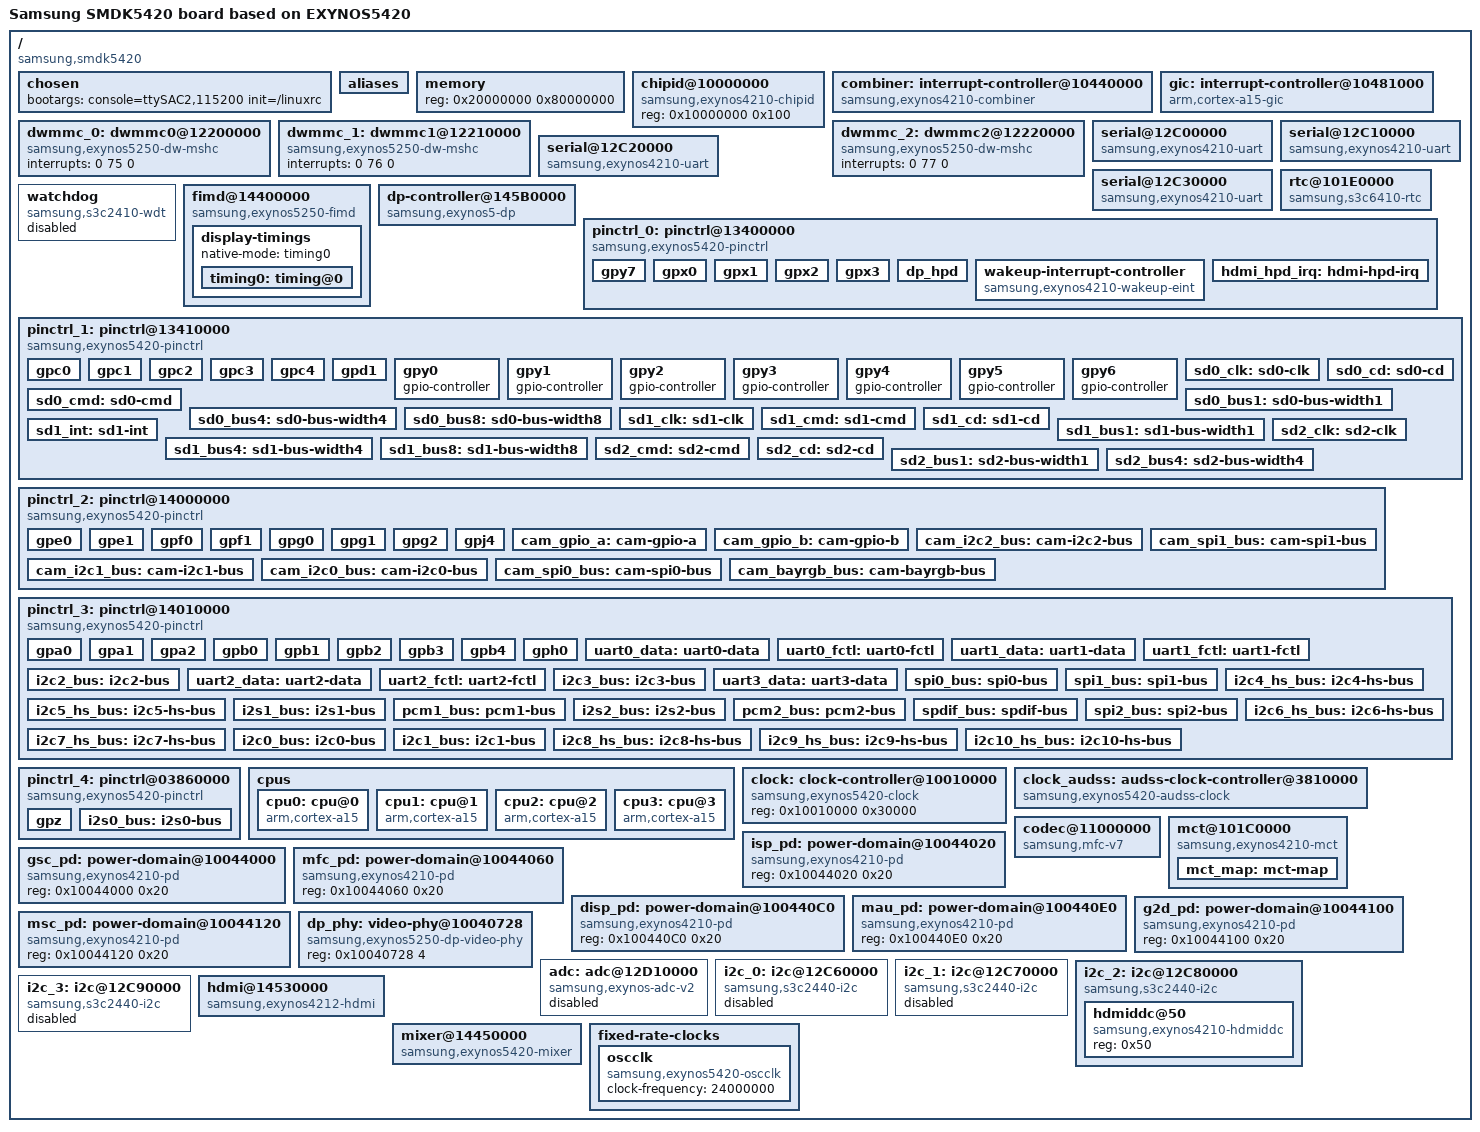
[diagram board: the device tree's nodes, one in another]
/*
 * SAMSUNG SMDK5420 board device tree source
 *
 * Copyright (c) 2013 Samsung Electronics Co., Ltd.
 *		http://www.samsung.com
 *
 * This program is free software; you can redistribute it and/or modify
 * it under the terms of the GNU General Public License version 2 as
 * published by the Free Software Foundation.
*/



/* #include "skeleton.dtsi" */

/ {
	/* ARM10C 20131012 */
	#address-cells = <1>;
	#size-cells = <1>;
	chosen { };
	aliases { };
	memory { device_type = "memory"; reg = <0 0>; };
};

/* #include "exynos5.dtsi" */

/ {
	interrupt-parent = <&gic>;

	chipid@10000000 {
		compatible = "samsung,exynos4210-chipid";
		reg = <0x10000000 0x100>;
	};

	combiner:interrupt-controller@10440000 {
		compatible = "samsung,exynos4210-combiner";
		#interrupt-cells = <2>;
		interrupt-controller;
		samsung,combiner-nr = <32>;
		reg = <0x10440000 0x1000>;
		interrupts =	<0 0 0>, <0 1 0>, <0 2 0>, <0 3 0>,
				<0 4 0>, <0 5 0>, <0 6 0>, <0 7 0>,
				<0 8 0>, <0 9 0>, <0 10 0>, <0 11 0>,
				<0 12 0>, <0 13 0>, <0 14 0>, <0 15 0>,
				<0 16 0>, <0 17 0>, <0 18 0>, <0 19 0>,
				<0 20 0>, <0 21 0>, <0 22 0>, <0 23 0>,
				<0 24 0>, <0 25 0>, <0 26 0>, <0 27 0>,
				<0 28 0>, <0 29 0>, <0 30 0>, <0 31 0>;
	};

	gic:interrupt-controller@10481000 {
		compatible = "arm,cortex-a15-gic", "arm,cortex-a9-gic";
		#interrupt-cells = <3>;
		interrupt-controller;
		reg =	<0x10481000 0x1000>,
			<0x10482000 0x1000>,
			<0x10484000 0x2000>,
			<0x10486000 0x2000>;
		interrupts = <1 9 0xf04>;
	};

	dwmmc_0: dwmmc0@12200000 {
		compatible = "samsung,exynos5250-dw-mshc";
		interrupts = <0 75 0>;
		#address-cells = <1>;
		#size-cells = <0>;
	};

	dwmmc_1: dwmmc1@12210000 {
		compatible = "samsung,exynos5250-dw-mshc";
		interrupts = <0 76 0>;
		#address-cells = <1>;
		#size-cells = <0>;
	};

	dwmmc_2: dwmmc2@12220000 {
		compatible = "samsung,exynos5250-dw-mshc";
		interrupts = <0 77 0>;
		#address-cells = <1>;
		#size-cells = <0>;
	};

	serial@12C00000 {
		compatible = "samsung,exynos4210-uart";
		reg = <0x12C00000 0x100>;
		interrupts = <0 51 0>;
	};

	serial@12C10000 {
		compatible = "samsung,exynos4210-uart";
		reg = <0x12C10000 0x100>;
		interrupts = <0 52 0>;
	};

	serial@12C20000 {
		compatible = "samsung,exynos4210-uart";
		reg = <0x12C20000 0x100>;
		interrupts = <0 53 0>;
	};

	serial@12C30000 {
		compatible = "samsung,exynos4210-uart";
		reg = <0x12C30000 0x100>;
		interrupts = <0 54 0>;
	};

	rtc@101E0000 {
		compatible = "samsung,s3c6410-rtc";
		reg = <0x101E0000 0x100>;
		interrupts = <0 43 0>, <0 44 0>;
		status = "disabled";
	};

	watchdog {
		compatible = "samsung,s3c2410-wdt";
		reg = <0x101D0000 0x100>;
		interrupts = <0 42 0>;
		status = "disabled";
	};

	fimd@14400000 {
		compatible = "samsung,exynos5250-fimd";
		interrupt-parent = <&combiner>;
		reg = <0x14400000 0x40000>;
		interrupt-names = "fifo", "vsync", "lcd_sys";
		interrupts = <18 4>, <18 5>, <18 6>;
		status = "disabled";
	};

	dp-controller@145B0000 {
		compatible = "samsung,exynos5-dp";
		reg = <0x145B0000 0x1000>;
		interrupts = <10 3>;
		interrupt-parent = <&combiner>;
		#address-cells = <1>;
		#size-cells = <0>;
		status = "disabled";
	};
};

/* #include "exynos5420-pinctrl.dtsi" */
/ {
	pinctrl@13400000 {
		gpy7: gpy7 {
			gpio-controller;
			#gpio-cells = <2>;

			interrupt-controller;
			#interrupt-cells = <2>;
		};

		gpx0: gpx0 {
			gpio-controller;
			#gpio-cells = <2>;

			interrupt-controller;
			interrupt-parent = <&combiner>;
			#interrupt-cells = <2>;
			interrupts = <23 0>, <24 0>, <25 0>, <25 1>,
				     <26 0>, <26 1>, <27 0>, <27 1>;
		};

		gpx1: gpx1 {
			gpio-controller;
			#gpio-cells = <2>;

			interrupt-controller;
			interrupt-parent = <&combiner>;
			#interrupt-cells = <2>;
			interrupts = <28 0>, <28 1>, <29 0>, <29 1>,
				     <30 0>, <30 1>, <31 0>, <31 1>;
		};

		gpx2: gpx2 {
			gpio-controller;
			#gpio-cells = <2>;

			interrupt-controller;
			#interrupt-cells = <2>;
		};

		gpx3: gpx3 {
			gpio-controller;
			#gpio-cells = <2>;

			interrupt-controller;
			#interrupt-cells = <2>;
		};

		dp_hpd: dp_hpd {
			samsung,pins = "gpx0-7";
			samsung,pin-function = <3>;
			samsung,pin-pud = <0>;
			samaung,pin-drv = <0>;
		};
	};

	pinctrl@13410000 {
		gpc0: gpc0 {
			gpio-controller;
			#gpio-cells = <2>;

			interrupt-controller;
			#interrupt-cells = <2>;
		};

		gpc1: gpc1 {
			gpio-controller;
			#gpio-cells = <2>;

			interrupt-controller;
			#interrupt-cells = <2>;
		};

		gpc2: gpc2 {
			gpio-controller;
			#gpio-cells = <2>;

			interrupt-controller;
			#interrupt-cells = <2>;
		};

		gpc3: gpc3 {
			gpio-controller;
			#gpio-cells = <2>;

			interrupt-controller;
			#interrupt-cells = <2>;
		};

		gpc4: gpc4 {
			gpio-controller;
			#gpio-cells = <2>;

			interrupt-controller;
			#interrupt-cells = <2>;
		};

		gpd1: gpd1 {
			gpio-controller;
			#gpio-cells = <2>;

			interrupt-controller;
			#interrupt-cells = <2>;
		};

		gpy0: gpy0 {
			gpio-controller;
			#gpio-cells = <2>;
		};

		gpy1: gpy1 {
			gpio-controller;
			#gpio-cells = <2>;
		};

		gpy2: gpy2 {
			gpio-controller;
			#gpio-cells = <2>;
		};

		gpy3: gpy3 {
			gpio-controller;
			#gpio-cells = <2>;
		};

		gpy4: gpy4 {
			gpio-controller;
			#gpio-cells = <2>;
		};

		gpy5: gpy5 {
			gpio-controller;
			#gpio-cells = <2>;
		};

		gpy6: gpy6 {
			gpio-controller;
			#gpio-cells = <2>;
		};

		sd0_clk: sd0-clk {
			samsung,pins = "gpc0-0";
			samsung,pin-function = <2>;
			samsung,pin-pud = <0>;
			samsung,pin-drv = <3>;
		};

		sd0_cmd: sd0-cmd {
			samsung,pins = "gpc0-1";
			samsung,pin-function = <2>;
			samsung,pin-pud = <0>;
			samsung,pin-drv = <3>;
		};

		sd0_cd: sd0-cd {
			samsung,pins = "gpc0-2";
			samsung,pin-function = <2>;
			samsung,pin-pud = <3>;
			samsung,pin-drv = <3>;
		};

		sd0_bus1: sd0-bus-width1 {
			samsung,pins = "gpc0-3";
			samsung,pin-function = <2>;
			samsung,pin-pud = <3>;
			samsung,pin-drv = <3>;
		};

		sd0_bus4: sd0-bus-width4 {
			samsung,pins = "gpc0-4", "gpc0-5", "gpc0-6";
			samsung,pin-function = <2>;
			samsung,pin-pud = <3>;
			samsung,pin-drv = <3>;
		};

		sd0_bus8: sd0-bus-width8 {
			samsung,pins = "gpc3-0", "gpc3-1", "gpc3-2", "gpc3-3";
			samsung,pin-function = <2>;
			samsung,pin-pud = <3>;
			samsung,pin-drv = <3>;
		};

		sd1_clk: sd1-clk {
			samsung,pins = "gpc1-0";
			samsung,pin-function = <2>;
			samsung,pin-pud = <0>;
			samsung,pin-drv = <3>;
		};

		sd1_cmd: sd1-cmd {
			samsung,pins = "gpc1-1";
			samsung,pin-function = <2>;
			samsung,pin-pud = <0>;
			samsung,pin-drv = <3>;
		};

		sd1_cd: sd1-cd {
			samsung,pins = "gpc1-2";
			samsung,pin-function = <2>;
			samsung,pin-pud = <3>;
			samsung,pin-drv = <3>;
		};

		sd1_int: sd1-int {
			samsung,pins = "gpd1-1";
			samsung,pin-function = <2>;
			samsung,pin-pud = <3>;
			samsung,pin-drv = <0>;
		};

		sd1_bus1: sd1-bus-width1 {
			samsung,pins = "gpc1-3";
			samsung,pin-function = <2>;
			samsung,pin-pud = <3>;
			samsung,pin-drv = <3>;
		};

		sd1_bus4: sd1-bus-width4 {
			samsung,pins = "gpc1-4", "gpc1-5", "gpc1-6";
			samsung,pin-function = <2>;
			samsung,pin-pud = <3>;
			samsung,pin-drv = <3>;
		};

		sd1_bus8: sd1-bus-width8 {
			samsung,pins = "gpd1-4", "gpd1-5", "gpd1-6", "gpd1-7";
			samsung,pin-function = <2>;
			samsung,pin-pud = <3>;
			samsung,pin-drv = <3>;
		};

		sd2_clk: sd2-clk {
			samsung,pins = "gpc2-0";
			samsung,pin-function = <2>;
			samsung,pin-pud = <0>;
			samsung,pin-drv = <3>;
		};

		sd2_cmd: sd2-cmd {
			samsung,pins = "gpc2-1";
			samsung,pin-function = <2>;
			samsung,pin-pud = <0>;
			samsung,pin-drv = <3>;
		};

		sd2_cd: sd2-cd {
			samsung,pins = "gpc2-2";
			samsung,pin-function = <2>;
			samsung,pin-pud = <3>;
			samsung,pin-drv = <3>;
		};

		sd2_bus1: sd2-bus-width1 {
			samsung,pins = "gpc2-3";
			samsung,pin-function = <2>;
			samsung,pin-pud = <3>;
			samsung,pin-drv = <3>;
		};

		sd2_bus4: sd2-bus-width4 {
			samsung,pins = "gpc2-4", "gpc2-5", "gpc2-6";
			samsung,pin-function = <2>;
			samsung,pin-pud = <3>;
			samsung,pin-drv = <3>;
		};
	};

	pinctrl@14000000 {
		gpe0: gpe0 {
			gpio-controller;
			#gpio-cells = <2>;

			interrupt-controller;
			#interrupt-cells = <2>;
		};

		gpe1: gpe1 {
			gpio-controller;
			#gpio-cells = <2>;

			interrupt-controller;
			#interrupt-cells = <2>;
		};

		gpf0: gpf0 {
			gpio-controller;
			#gpio-cells = <2>;

			interrupt-controller;
			#interrupt-cells = <2>;
		};

		gpf1: gpf1 {
			gpio-controller;
			#gpio-cells = <2>;

			interrupt-controller;
			#interrupt-cells = <2>;
		};

		gpg0: gpg0 {
			gpio-controller;
			#gpio-cells = <2>;

			interrupt-controller;
			#interrupt-cells = <2>;
		};

		gpg1: gpg1 {
			gpio-controller;
			#gpio-cells = <2>;

			interrupt-controller;
			#interrupt-cells = <2>;
		};

		gpg2: gpg2 {
			gpio-controller;
			#gpio-cells = <2>;

			interrupt-controller;
			#interrupt-cells = <2>;
		};

		gpj4: gpj4 {
			gpio-controller;
			#gpio-cells = <2>;

			interrupt-controller;
			#interrupt-cells = <2>;
		};

		cam_gpio_a: cam-gpio-a {
			samsung,pins = "gpe0-0", "gpe0-1", "gpe0-2", "gpe0-3",
				       "gpe0-4", "gpe0-5", "gpe0-6", "gpe0-7",
				       "gpe1-0", "gpe1-1";
			samsung,pin-function = <2>;
			samsung,pin-pud = <0>;
			samsung,pin-drv = <0>;
		};

		cam_gpio_b: cam-gpio-b {
			samsung,pins = "gpf0-0", "gpf0-1", "gpf0-2", "gpf0-3",
				       "gpf1-0", "gpf1-1", "gpf1-2", "gpf1-3";
			samsung,pin-function = <3>;
			samsung,pin-pud = <0>;
			samsung,pin-drv = <0>;
		};

		cam_i2c2_bus: cam-i2c2-bus {
			samsung,pins = "gpf0-4", "gpf0-5";
			samsung,pin-function = <2>;
			samsung,pin-pud = <3>;
			samsung,pin-drv = <0>;
		};
		cam_spi1_bus: cam-spi1-bus {
			samsung,pins = "gpe0-4", "gpe0-5", "gpf0-2", "gpf0-3";
			samsung,pin-function = <4>;
			samsung,pin-pud = <0>;
			samsung,pin-drv = <0>;
		};

		cam_i2c1_bus: cam-i2c1-bus {
			samsung,pins = "gpf0-2", "gpf0-3";
			samsung,pin-function = <2>;
			samsung,pin-pud = <3>;
			samsung,pin-drv = <0>;
		};

		cam_i2c0_bus: cam-i2c0-bus {
			samsung,pins = "gpf0-0", "gpf0-1";
			samsung,pin-function = <2>;
			samsung,pin-pud = <3>;
			samsung,pin-drv = <0>;
		};

		cam_spi0_bus: cam-spi0-bus {
			samsung,pins = "gpf1-0", "gpf1-1", "gpf1-2", "gpf1-3";
			samsung,pin-function = <2>;
			samsung,pin-pud = <0>;
			samsung,pin-drv = <0>;
		};

		cam_bayrgb_bus: cam-bayrgb-bus {
			samsung,pins = "gpg0-0", "gpg0-1", "gpg0-2", "gpg0-3",
				       "gpg0-4", "gpg0-5", "gpg0-6", "gpg0-7",
				       "gpg1-0", "gpg1-1", "gpg1-2", "gpg1-3",
				       "gpg1-4", "gpg1-5", "gpg1-6", "gpg1-7",
				       "gpg2-0";
			samsung,pin-function = <2>;
			samsung,pin-pud = <0>;
			samsung,pin-drv = <0>;
		};
	};

	pinctrl@14010000 {
		gpa0: gpa0 {
			gpio-controller;
			#gpio-cells = <2>;

			interrupt-controller;
			#interrupt-cells = <2>;
		};

		gpa1: gpa1 {
			gpio-controller;
			#gpio-cells = <2>;

			interrupt-controller;
			#interrupt-cells = <2>;
		};

		gpa2: gpa2 {
			gpio-controller;
			#gpio-cells = <2>;

			interrupt-controller;
			#interrupt-cells = <2>;
		};

		gpb0: gpb0 {
			gpio-controller;
			#gpio-cells = <2>;

			interrupt-controller;
			#interrupt-cells = <2>;
		};

		gpb1: gpb1 {
			gpio-controller;
			#gpio-cells = <2>;

			interrupt-controller;
			#interrupt-cells = <2>;
		};

		gpb2: gpb2 {
			gpio-controller;
			#gpio-cells = <2>;

			interrupt-controller;
			#interrupt-cells = <2>;
		};

		gpb3: gpb3 {
			gpio-controller;
			#gpio-cells = <2>;

			interrupt-controller;
			#interrupt-cells = <2>;
		};

		gpb4: gpb4 {
			gpio-controller;
			#gpio-cells = <2>;

			interrupt-controller;
			#interrupt-cells = <2>;
		};

		gph0: gph0 {
			gpio-controller;
			#gpio-cells = <2>;

			interrupt-controller;
			#interrupt-cells = <2>;
		};

		uart0_data: uart0-data {
			samsung,pins = "gpa0-0", "gpa0-1";
			samsung,pin-function = <2>;
			samsung,pin-pud = <0>;
			samsung,pin-drv = <0>;
		};

		uart0_fctl: uart0-fctl {
			samsung,pins = "gpa0-2", "gpa0-3";
			samsung,pin-function = <2>;
			samsung,pin-pud = <0>;
			samsung,pin-drv = <0>;
		};

		uart1_data: uart1-data {
			samsung,pins = "gpa0-4", "gpa0-5";
			samsung,pin-function = <2>;
			samsung,pin-pud = <0>;
			samsung,pin-drv = <0>;
		};

		uart1_fctl: uart1-fctl {
			samsung,pins = "gpa0-6", "gpa0-7";
			samsung,pin-function = <2>;
			samsung,pin-pud = <0>;
			samsung,pin-drv = <0>;
		};

		i2c2_bus: i2c2-bus {
			samsung,pins = "gpa0-6", "gpa0-7";
			samsung,pin-function = <3>;
			samsung,pin-pud = <3>;
			samsung,pin-drv = <0>;
		};

		uart2_data: uart2-data {
			samsung,pins = "gpa1-0", "gpa1-1";
			samsung,pin-function = <2>;
			samsung,pin-pud = <0>;
			samsung,pin-drv = <0>;
		};

		uart2_fctl: uart2-fctl {
			samsung,pins = "gpa1-2", "gpa1-3";
			samsung,pin-function = <2>;
			samsung,pin-pud = <0>;
			samsung,pin-drv = <0>;
		};

		i2c3_bus: i2c3-bus {
			samsung,pins = "gpa1-2", "gpa1-3";
			samsung,pin-function = <3>;
			samsung,pin-pud = <3>;
			samsung,pin-drv = <0>;
		};

		uart3_data: uart3-data {
			samsung,pins = "gpa1-4", "gpa1-5";
			samsung,pin-function = <2>;
			samsung,pin-pud = <0>;
			samsung,pin-drv = <0>;
		};

		spi0_bus: spi0-bus {
			samsung,pins = "gpa2-0", "gpa2-1", "gpa2-2", "gpa2-3";
			samsung,pin-function = <2>;
			samsung,pin-pud = <3>;
			samsung,pin-drv = <0>;
		};

		spi1_bus: spi1-bus {
			samsung,pins = "gpa2-4", "gpa2-6", "gpa2-7";
			samsung,pin-function = <2>;
			samsung,pin-pud = <3>;
			samsung,pin-drv = <0>;
		};

		i2c4_hs_bus: i2c4-hs-bus {
			samsung,pins = "gpa2-0", "gpa2-1";
			samsung,pin-function = <3>;
			samsung,pin-pud = <3>;
			samsung,pin-drv = <0>;
		};

		i2c5_hs_bus: i2c5-hs-bus {
			samsung,pins = "gpa2-2", "gpa2-3";
			samsung,pin-function = <3>;
			samsung,pin-pud = <3>;
			samsung,pin-drv = <0>;
		};

		i2s1_bus: i2s1-bus {
			samsung,pins = "gpb0-0", "gpb0-1", "gpb0-2", "gpb0-3",
					"gpb0-4";
			samsung,pin-function = <2>;
			samsung,pin-pud = <0>;
			samsung,pin-drv = <0>;
		};

		pcm1_bus: pcm1-bus {
			samsung,pins = "gpb0-0", "gpb0-1", "gpb0-2", "gpb0-3",
					"gpb0-4";
			samsung,pin-function = <3>;
			samsung,pin-pud = <0>;
			samsung,pin-drv = <0>;
		};

		i2s2_bus: i2s2-bus {
			samsung,pins = "gpb1-0", "gpb1-1", "gpb1-2", "gpb1-3",
					"gpb1-4";
			samsung,pin-function = <2>;
			samsung,pin-pud = <0>;
			samsung,pin-drv = <0>;
		};

		pcm2_bus: pcm2-bus {
			samsung,pins = "gpb1-0", "gpb1-1", "gpb1-2", "gpb1-3",
					"gpb1-4";
			samsung,pin-function = <3>;
			samsung,pin-pud = <0>;
			samsung,pin-drv = <0>;
		};

		spdif_bus: spdif-bus {
			samsung,pins = "gpb1-0", "gpb1-1";
			samsung,pin-function = <4>;
			samsung,pin-pud = <0>;
			samsung,pin-drv = <0>;
		};

		spi2_bus: spi2-bus {
			samsung,pins = "gpb1-1", "gpb1-3", "gpb1-4";
			samsung,pin-function = <5>;
			samsung,pin-pud = <3>;
			samsung,pin-drv = <0>;
		};

		i2c6_hs_bus: i2c6-hs-bus {
			samsung,pins = "gpb1-3", "gpb1-4";
			samsung,pin-function = <4>;
			samsung,pin-pud = <3>;
			samsung,pin-drv = <0>;
		};

		i2c7_hs_bus: i2c7-hs-bus {
			samsung,pins = "gpb2-2", "gpb2-3";
			samsung,pin-function = <3>;
			samsung,pin-pud = <3>;
			samsung,pin-drv = <0>;
		};

		i2c0_bus: i2c0-bus {
			samsung,pins = "gpb3-0", "gpb3-1";
			samsung,pin-function = <2>;
			samsung,pin-pud = <3>;
			samsung,pin-drv = <0>;
		};

		i2c1_bus: i2c1-bus {
			samsung,pins = "gpb3-2", "gpb3-3";
			samsung,pin-function = <2>;
			samsung,pin-pud = <3>;
			samsung,pin-drv = <0>;
		};

		i2c8_hs_bus: i2c8-hs-bus {
			samsung,pins = "gpb3-4", "gpb3-5";
			samsung,pin-function = <2>;
			samsung,pin-pud = <3>;
			samsung,pin-drv = <0>;
		};

		i2c9_hs_bus: i2c9-hs-bus {
			samsung,pins = "gpb3-6", "gpb3-7";
			samsung,pin-function = <2>;
			samsung,pin-pud = <3>;
			samsung,pin-drv = <0>;
		};

		i2c10_hs_bus: i2c10-hs-bus {
			samsung,pins = "gpb4-0", "gpb4-1";
			samsung,pin-function = <2>;
			samsung,pin-pud = <3>;
			samsung,pin-drv = <0>;
		};
	};

	pinctrl@03860000 {
		gpz: gpz {
			gpio-controller;
			#gpio-cells = <2>;

			interrupt-controller;
			#interrupt-cells = <2>;
		};

		i2s0_bus: i2s0-bus {
			samsung,pins = "gpz-0", "gpz-1", "gpz-2", "gpz-3",
					"gpz-4", "gpz-5", "gpz-6";
			samsung,pin-function = <2>;
			samsung,pin-pud = <0>;
			samsung,pin-drv = <0>;
		};
	};
};

/* #include <dt-bindings/clk/exynos-audss-clk.h> */
#ifndef _DT_BINDINGS_CLK_EXYNOS_AUDSS_H
#define _DT_BINDINGS_CLK_EXYNOS_AUDSS_H

#define EXYNOS_MOUT_AUDSS	0
#define EXYNOS_MOUT_I2S	1
#define EXYNOS_DOUT_SRP	2
#define EXYNOS_DOUT_AUD_BUS	3
#define EXYNOS_DOUT_I2S	4
#define EXYNOS_SRP_CLK		5
#define EXYNOS_I2S_BUS		6
#define EXYNOS_SCLK_I2S	7
#define EXYNOS_PCM_BUS		8
#define EXYNOS_SCLK_PCM	9

#define EXYNOS_AUDSS_MAX_CLKS	10

#endif

/* #include "exynos5420.dtsi" */

/ {
	compatible = "samsung,exynos5420";

	aliases {
		pinctrl0 = &pinctrl_0;
		pinctrl1 = &pinctrl_1;
		pinctrl2 = &pinctrl_2;
		pinctrl3 = &pinctrl_3;
		pinctrl4 = &pinctrl_4;
		i2c0 = &i2c_0;
		i2c1 = &i2c_1;
		i2c2 = &i2c_2;
		i2c3 = &i2c_3;
	};

	cpus {
		#address-cells = <1>;
		#size-cells = <0>;

		cpu0: cpu@0 {
			device_type = "cpu";
			compatible = "arm,cortex-a15";
			reg = <0x0>;
			clock-frequency = <1800000000>;
		};

		cpu1: cpu@1 {
			device_type = "cpu";
			compatible = "arm,cortex-a15";
			reg = <0x1>;
			clock-frequency = <1800000000>;
		};

		cpu2: cpu@2 {
			device_type = "cpu";
			compatible = "arm,cortex-a15";
			reg = <0x2>;
			clock-frequency = <1800000000>;
		};

		cpu3: cpu@3 {
			device_type = "cpu";
			compatible = "arm,cortex-a15";
			reg = <0x3>;
			clock-frequency = <1800000000>;
		};
	};

	clock: clock-controller@10010000 {
		compatible = "samsung,exynos5420-clock";
		reg = <0x10010000 0x30000>;
		#clock-cells = <1>;
	};

	clock_audss: audss-clock-controller@3810000 {
		compatible = "samsung,exynos5420-audss-clock";
		reg = <0x03810000 0x0C>;
		#clock-cells = <1>;
		clocks = <&clock 148>;
		clock-names = "sclk_audio";
	};

	codec@11000000 {
		compatible = "samsung,mfc-v7";
		reg = <0x11000000 0x10000>;
		interrupts = <0 96 0>;
		clocks = <&clock 401>;
		clock-names = "mfc";
	};

	mct@101C0000 {
		compatible = "samsung,exynos4210-mct";
		reg = <0x101C0000 0x800>;
		interrupt-controller;
		#interrups-cells = <1>;
		interrupt-parent = <&mct_map>;
		interrupts = <0>, <1>, <2>, <3>, <4>, <5>, <6>, <7>;
		clocks = <&clock 1>, <&clock 315>;
		clock-names = "fin_pll", "mct";

		mct_map: mct-map {
			#interrupt-cells = <1>;
			#address-cells = <0>;
			#size-cells = <0>;
			interrupt-map = <0 &combiner 23 3>,
					<1 &combiner 23 4>,
					<2 &combiner 25 2>,
					<3 &combiner 25 3>,
					<4 &gic 0 120 0>,
					<5 &gic 0 121 0>,
					<6 &gic 0 122 0>,
					<7 &gic 0 123 0>;
		};
	};

	gsc_pd: power-domain@10044000 {
		compatible = "samsung,exynos4210-pd";
		reg = <0x10044000 0x20>;
	};

	isp_pd: power-domain@10044020 {
		compatible = "samsung,exynos4210-pd";
		reg = <0x10044020 0x20>;
	};

	mfc_pd: power-domain@10044060 {
		compatible = "samsung,exynos4210-pd";
		reg = <0x10044060 0x20>;
	};

	disp_pd: power-domain@100440C0 {
		compatible = "samsung,exynos4210-pd";
		reg = <0x100440C0 0x20>;
	};

	mau_pd: power-domain@100440E0 {
		compatible = "samsung,exynos4210-pd";
		reg = <0x100440E0 0x20>;
	};

	g2d_pd: power-domain@10044100 {
		compatible = "samsung,exynos4210-pd";
		reg = <0x10044100 0x20>;
	};

	msc_pd: power-domain@10044120 {
		compatible = "samsung,exynos4210-pd";
		reg = <0x10044120 0x20>;
	};

	pinctrl_0: pinctrl@13400000 {
		compatible = "samsung,exynos5420-pinctrl";
		reg = <0x13400000 0x1000>;
		interrupts = <0 45 0>;

		wakeup-interrupt-controller {
			compatible = "samsung,exynos4210-wakeup-eint";
			interrupt-parent = <&gic>;
			interrupts = <0 32 0>;
		};
	};

	pinctrl_1: pinctrl@13410000 {
		compatible = "samsung,exynos5420-pinctrl";
		reg = <0x13410000 0x1000>;
		interrupts = <0 78 0>;
	};

	pinctrl_2: pinctrl@14000000 {
		compatible = "samsung,exynos5420-pinctrl";
		reg = <0x14000000 0x1000>;
		interrupts = <0 46 0>;
	};

	pinctrl_3: pinctrl@14010000 {
		compatible = "samsung,exynos5420-pinctrl";
		reg = <0x14010000 0x1000>;
		interrupts = <0 50 0>;
	};

	pinctrl_4: pinctrl@03860000 {
		compatible = "samsung,exynos5420-pinctrl";
		reg = <0x03860000 0x1000>;
		interrupts = <0 47 0>;
	};

	rtc@101E0000 {
		clocks = <&clock 317>;
		clock-names = "rtc";
		status = "okay";
	};

	serial@12C00000 {
		clocks = <&clock 257>, <&clock 128>;
		clock-names = "uart", "clk_uart_baud0";
	};

	serial@12C10000 {
		clocks = <&clock 258>, <&clock 129>;
		clock-names = "uart", "clk_uart_baud0";
	};

	serial@12C20000 {
		clocks = <&clock 259>, <&clock 130>;
		clock-names = "uart", "clk_uart_baud0";
	};

	serial@12C30000 {
		clocks = <&clock 260>, <&clock 131>;
		clock-names = "uart", "clk_uart_baud0";
	};

	dp_phy: video-phy@10040728 {
		compatible = "samsung,exynos5250-dp-video-phy";
		reg = <0x10040728 4>;
		#phy-cells = <0>;
	};

	dp-controller@145B0000 {
		clocks = <&clock 412>;
		clock-names = "dp";
		phys = <&dp_phy>;
		phy-names = "dp";
	};

	fimd@14400000 {
		samsung,power-domain = <&disp_pd>;
		clocks = <&clock 147>, <&clock 421>;
		clock-names = "sclk_fimd", "fimd";
	};

	adc: adc@12D10000 {
		compatible = "samsung,exynos-adc-v2";
		reg = <0x12D10000 0x100>, <0x10040720 0x4>;
		interrupts = <0 106 0>;
		clocks = <&clock 270>;
		clock-names = "adc";
		#io-channel-cells = <1>;
		io-channel-ranges;
		status = "disabled";
	};

	i2c_0: i2c@12C60000 {
		compatible = "samsung,s3c2440-i2c";
		reg = <0x12C60000 0x100>;
		interrupts = <0 56 0>;
		#address-cells = <1>;
		#size-cells = <0>;
		clocks = <&clock 261>;
		clock-names = "i2c";
		pinctrl-names = "default";
		pinctrl-0 = <&i2c0_bus>;
		status = "disabled";
	};

	i2c_1: i2c@12C70000 {
		compatible = "samsung,s3c2440-i2c";
		reg = <0x12C70000 0x100>;
		interrupts = <0 57 0>;
		#address-cells = <1>;
		#size-cells = <0>;
		clocks = <&clock 262>;
		clock-names = "i2c";
		pinctrl-names = "default";
		pinctrl-0 = <&i2c1_bus>;
		status = "disabled";
	};

	i2c_2: i2c@12C80000 {
		compatible = "samsung,s3c2440-i2c";
		reg = <0x12C80000 0x100>;
		interrupts = <0 58 0>;
		#address-cells = <1>;
		#size-cells = <0>;
		clocks = <&clock 263>;
		clock-names = "i2c";
		pinctrl-names = "default";
		pinctrl-0 = <&i2c2_bus>;
		status = "disabled";
	};

	i2c_3: i2c@12C90000 {
		compatible = "samsung,s3c2440-i2c";
		reg = <0x12C90000 0x100>;
		interrupts = <0 59 0>;
		#address-cells = <1>;
		#size-cells = <0>;
		clocks = <&clock 264>;
		clock-names = "i2c";
		pinctrl-names = "default";
		pinctrl-0 = <&i2c3_bus>;
		status = "disabled";
	};

	hdmi@14530000 {
		compatible = "samsung,exynos4212-hdmi";
		reg = <0x14530000 0x70000>;
		interrupts = <0 95 0>;
		clocks = <&clock 413>, <&clock 143>, <&clock 768>,
			<&clock 158>, <&clock 640>;
		clock-names = "hdmi", "sclk_hdmi", "sclk_pixel",
			"sclk_hdmiphy", "mout_hdmi";
		status = "disabled";
	};

	mixer@14450000 {
		compatible = "samsung,exynos5420-mixer";
		reg = <0x14450000 0x10000>;
		interrupts = <0 94 0>;
		clocks = <&clock 431>, <&clock 143>;
		clock-names = "mixer", "sclk_hdmi";
	};
};

/dts-v1/;

/ {
	model = "Samsung SMDK5420 board based on EXYNOS5420";
	compatible = "samsung,smdk5420", "samsung,exynos5420";

	/* ARM10C 20131012 */
	memory {
		reg = <0x20000000 0x80000000>;
	};

	chosen {
		bootargs = "console=ttySAC2,115200 init=/linuxrc";
	};

	fixed-rate-clocks {
		oscclk {
			compatible = "samsung,exynos5420-oscclk";
			clock-frequency = <24000000>;
		};
	};

	dp-controller@145B0000 {
		pinctrl-names = "default";
		pinctrl-0 = <&dp_hpd>;
		samsung,color-space = <0>;
		samsung,dynamic-range = <0>;
		samsung,ycbcr-coeff = <0>;
		samsung,color-depth = <1>;
		samsung,link-rate = <0x0a>;
		samsung,lane-count = <4>;
		status = "okay";
	};

	fimd@14400000 {
		status = "okay";
		display-timings {
			native-mode = <&timing0>;
			timing0: timing@0 {
				clock-frequency = <50000>;
				hactive = <2560>;
				vactive = <1600>;
				hfront-porch = <48>;
				hback-porch = <80>;
				hsync-len = <32>;
				vback-porch = <16>;
				vfront-porch = <8>;
				vsync-len = <6>;
			};
		};
	};

	pinctrl@13400000 {
		hdmi_hpd_irq: hdmi-hpd-irq {
			samsung,pins = "gpx3-7";
			samsung,pin-function = <0>;
			samsung,pin-pud = <1>;
			samsung,pin-drv = <0>;
		};
	};

	hdmi@14530000 {
		status = "okay";
		hpd-gpio = <&gpx3 7 0>;
		pinctrl-names = "default";
		pinctrl-0 = <&hdmi_hpd_irq>;
	};

	i2c_2: i2c@12C80000 {
		samsung,i2c-sda-delay = <100>;
		samsung,i2c-max-bus-freq = <66000>;
		status = "okay";

		hdmiddc@50 {
			compatible = "samsung,exynos4210-hdmiddc";
			reg = <0x50>;
		};
	};
};
